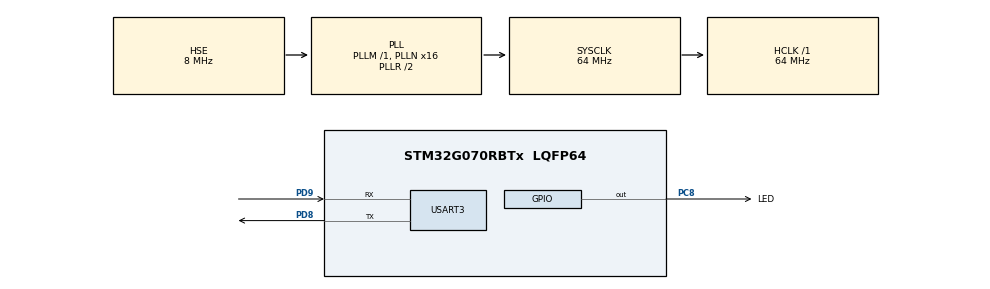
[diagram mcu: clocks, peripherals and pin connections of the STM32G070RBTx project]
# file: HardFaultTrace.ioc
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FREERTOS.Tasks01=defaultTask,24,128,StartDefaultTask,Default,NULL,Dynamic,NULL,NULL
Mcu.Family=STM32G0
Mcu.Name=STM32G070RBTx
Mcu.Package=LQFP64
NVIC.TIM17_IRQn=true\:3\:0\:false\:false\:true\:false\:false\:true
NVIC.TimeBase=TIM17_IRQn
NVIC.TimeBaseIP=TIM17
PA13.Mode=Serial_Wire
PA13.Signal=SYS_SWDIO
PA14-BOOT0.Mode=Serial_Wire
PA14-BOOT0.Signal=SYS_SWCLK
PC8.GPIO_Label=LED
PC8.Signal=GPIO_Output
PD8.Mode=Asynchronous
PD8.Signal=USART3_TX
PD9.Mode=Asynchronous
PD9.Signal=USART3_RX
PF0-OSC_IN\ (PF0).Mode=HSE-External-Oscillator
PF0-OSC_IN\ (PF0).Signal=RCC_OSC_IN
PF1-OSC_OUT\ (PF1).Mode=HSE-External-Oscillator
PF1-OSC_OUT\ (PF1).Signal=RCC_OSC_OUT
ProjectManager.HeapSize=0x200
ProjectManager.StackSize=0x400
ProjectManager.TargetToolchain=MDK-ARM V5.32
RCC.ADCFreq_Value=64000000
RCC.AHBFreq_Value=64000000
RCC.CortexFreq_Value=64000000
RCC.EXTERNAL_CLOCK_VALUE=48000
RCC.HCLKFreq_Value=64000000
RCC.HSE_VALUE=8000000
RCC.HSI_VALUE=16000000
RCC.LSE_VALUE=32768
RCC.PLLN=16
RCC.PLLSourceVirtual=RCC_PLLSOURCE_HSE
RCC.SYSCLKFreq_VALUE=64000000
RCC.SYSCLKSource=RCC_SYSCLKSOURCE_PLLCLK
RCC.VCOOutputFreq_Value=128000000
USART3.VirtualMode-Asynchronous=VM_ASYNC
VP_FREERTOS_VS_CMSIS_V2.Mode=CMSIS_V2
VP_SYS_VS_DBSignals.Mode=DisableDeadBatterySignals
VP_SYS_VS_tim17.Mode=TIM17
board=custom

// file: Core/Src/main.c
/* USER CODE BEGIN Header */
/**
  ******************************************************************************
  * @file           : main.c
  * @brief          : Main program body
  ******************************************************************************
  * @attention
  *
  * Copyright (c) 2022 STMicroelectronics.
  * All rights reserved.
  *
  * This software is licensed under terms that can be found in the LICENSE file
  * in the root directory of this software component.
  * If no LICENSE file comes with this software, it is provided AS-IS.
  *
  ******************************************************************************
  */
/* USER CODE END Header */
#include "main.h"
#include "cmsis_os.h"
#include "usart.h"
#include "gpio.h"

/* USER CODE BEGIN Includes */
#include <stdio.h>
#include "cm_backtrace.h"
/* USER CODE END Includes */

void SystemClock_Config(void);
void MX_FREERTOS_Init(void);

/* USER CODE BEGIN 0 */
int fputc(int ch, FILE *f) {
	HAL_UART_Transmit(&huart3, (uint8_t *)&ch, 1, 1000);

	return ch;
}
/* USER CODE END 0 */

int main(void)
{

  /* MCU Configuration--------------------------------------------------------*/

  /* Reset of all peripherals, Initializes the Flash interface and the Systick. */
  HAL_Init();

  /* Configure the system clock */
  SystemClock_Config();

  /* USER CODE BEGIN SysInit */
  cm_backtrace_init("HardFaultTrace", HARDWARE_VERSION, SOFTWARE_VERSION);

  /* USER CODE END SysInit */

  /* Initialize all configured peripherals */
  MX_GPIO_Init();
  MX_USART3_UART_Init();
  /* USER CODE BEGIN 2 */
  printf("System initialize finish. Starting..\r\n");
  /* USER CODE END 2 */

  /* Init scheduler */
  osKernelInitialize();  /* Call init function for freertos objects (in freertos.c) */
  MX_FREERTOS_Init();
  /* Start scheduler */
  osKernelStart();

  /* We should never get here as control is now taken by the scheduler */
  /* Infinite loop */
  while (1)
  {

  }
}

void SystemClock_Config(void)
{
  RCC_OscInitTypeDef RCC_OscInitStruct = {0};
  RCC_ClkInitTypeDef RCC_ClkInitStruct = {0};

  /** Configure the main internal regulator output voltage
  */
  HAL_PWREx_ControlVoltageScaling(PWR_REGULATOR_VOLTAGE_SCALE1);
  /** Initializes the RCC Oscillators according to the specified parameters
  * in the RCC_OscInitTypeDef structure.
  */
  RCC_OscInitStruct.OscillatorType = RCC_OSCILLATORTYPE_HSE;
  RCC_OscInitStruct.HSEState = RCC_HSE_ON;
  RCC_OscInitStruct.PLL.PLLState = RCC_PLL_ON;
  RCC_OscInitStruct.PLL.PLLSource = RCC_PLLSOURCE_HSE;
  RCC_OscInitStruct.PLL.PLLM = RCC_PLLM_DIV1;
  RCC_OscInitStruct.PLL.PLLN = 16;
  RCC_OscInitStruct.PLL.PLLP = RCC_PLLP_DIV2;
  RCC_OscInitStruct.PLL.PLLR = RCC_PLLR_DIV2;
  if (HAL_RCC_OscConfig(&RCC_OscInitStruct) != HAL_OK)
  {
    Error_Handler();
  }
  /** Initializes the CPU, AHB and APB buses clocks
  */
  RCC_ClkInitStruct.ClockType = RCC_CLOCKTYPE_HCLK|RCC_CLOCKTYPE_SYSCLK
                              |RCC_CLOCKTYPE_PCLK1;
  RCC_ClkInitStruct.SYSCLKSource = RCC_SYSCLKSOURCE_PLLCLK;
  RCC_ClkInitStruct.AHBCLKDivider = RCC_SYSCLK_DIV1;
  RCC_ClkInitStruct.APB1CLKDivider = RCC_HCLK_DIV1;

  if (HAL_RCC_ClockConfig(&RCC_ClkInitStruct, FLASH_LATENCY_2) != HAL_OK)
  {
    Error_Handler();
  }
}

void HAL_TIM_PeriodElapsedCallback(TIM_HandleTypeDef *htim)
{
  if (htim->Instance == TIM17) {
    HAL_IncTick();
  }
}

void Error_Handler(void)
{
  __disable_irq();
  while (1)
  {
  }
}

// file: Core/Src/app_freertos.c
/* USER CODE BEGIN Header */
/**
  ******************************************************************************
  * File Name          : app_freertos.c
  * Description        : Code for freertos applications
  ******************************************************************************
  * @attention
  *
  * Copyright (c) 2022 STMicroelectronics.
  * All rights reserved.
  *
  * This software is licensed under terms that can be found in the LICENSE file
  * in the root directory of this software component.
  * If no LICENSE file comes with this software, it is provided AS-IS.
  *
  ******************************************************************************
  */
/* USER CODE END Header */

#include "FreeRTOS.h"
#include "task.h"
#include "main.h"
#include "cmsis_os.h"

/* USER CODE BEGIN Includes */
#include <stdio.h>
/* USER CODE END Includes */

/* USER CODE BEGIN Variables */
static uint32_t times = 0;

/* USER CODE END Variables */
/* Definitions for defaultTask */
osThreadId_t defaultTaskHandle;
const osThreadAttr_t defaultTask_attributes = {
  .name = "defaultTask",
  .priority = (osPriority_t) osPriorityNormal,
  .stack_size = 128 * 4
};

/* USER CODE BEGIN FunctionPrototypes */
void fault_test_by_unalign(void) {
    volatile int * SCB_CCR = (volatile int *) 0xE000ED14; // SCB->CCR
    volatile int * p;
    volatile int value;

    *SCB_CCR |= (1 << 3); /* bit3: UNALIGN_TRP. */

    p = (int *) 0x00;
    value = *p;
    printf("addr:0x%02X value:0x%08X\r\n", (int) p, value);

    p = (int *) 0x04;
    value = *p;
    printf("addr:0x%02X value:0x%08X\r\n", (int) p, value);

    p = (int *) 0x03;
    value = *p;
    printf("addr:0x%02X value:0x%08X\r\n", (int) p, value);
}
/* USER CODE END FunctionPrototypes */

void StartDefaultTask(void *argument);

void MX_FREERTOS_Init(void); /* (MISRA C 2004 rule 8.1) */

void MX_FREERTOS_Init(void) {

  /* Create the thread(s) */
  /* creation of defaultTask */
  defaultTaskHandle = osThreadNew(StartDefaultTask, NULL, &defaultTask_attributes);

}

void StartDefaultTask(void *argument)
{
  /* USER CODE BEGIN StartDefaultTask */
  /* Infinite loop */
  for(;;)
  {
    if (times++ > 10) {
      fault_test_by_unalign();
    }

    HAL_GPIO_TogglePin(LED_GPIO_Port, LED_Pin);
    osDelay(100);
  }
  /* USER CODE END StartDefaultTask */
}
